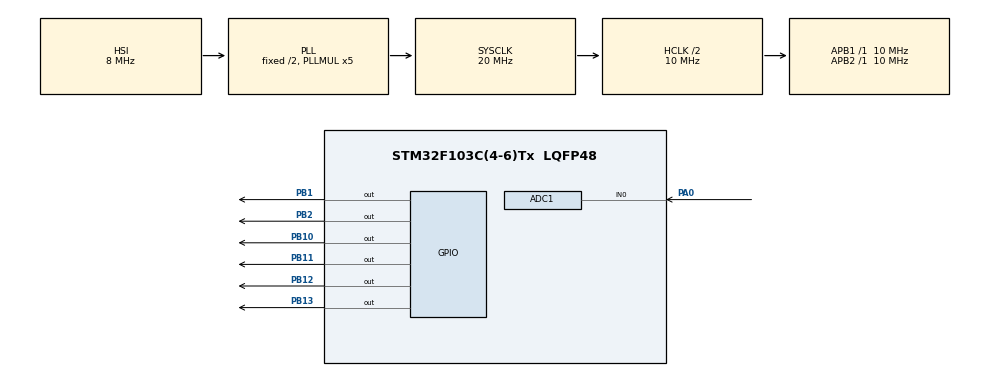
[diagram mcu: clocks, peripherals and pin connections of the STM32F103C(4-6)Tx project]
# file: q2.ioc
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ADC1.Channel-0\#ChannelRegularConversion=ADC_CHANNEL_0
ADC1.NbrOfConversionFlag=1
ADC1.Rank-0\#ChannelRegularConversion=1
ADC1.SamplingTime-0\#ChannelRegularConversion=ADC_SAMPLETIME_1CYCLE_5
ADC1.master=1
Mcu.Family=STM32F1
Mcu.Name=STM32F103C(4-6)Tx
Mcu.Package=LQFP48
NVIC.PriorityGroup=NVIC_PRIORITYGROUP_4
PA0-WKUP.Signal=ADCx_IN0
PB1.Signal=GPIO_Output
PB10.Signal=GPIO_Output
PB11.Signal=GPIO_Output
PB12.Signal=GPIO_Output
PB13.Signal=GPIO_Output
PB2.Signal=GPIO_Output
ProjectManager.HeapSize=0x200
ProjectManager.StackSize=0x400
ProjectManager.TargetToolchain=STM32CubeIDE
RCC.AHBCLKDivider=RCC_SYSCLK_DIV2
RCC.AHBFreq_Value=10000000
RCC.APB1Freq_Value=10000000
RCC.APB1TimFreq_Value=10000000
RCC.APB2Freq_Value=10000000
RCC.APB2TimFreq_Value=10000000
RCC.HCLKFreq_Value=10000000
RCC.PLLMUL=RCC_PLL_MUL5
RCC.SYSCLKFreq_VALUE=20000000
RCC.SYSCLKSource=RCC_SYSCLKSOURCE_PLLCLK
RCC.USBFreq_Value=20000000
SH.ADCx_IN0.0=ADC1_IN0,IN0
VP_SYS_VS_ND.Mode=No_Debug
board=custom

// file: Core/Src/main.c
/* USER CODE BEGIN Header */
/* USER CODE END Header */
#include "main.h"
#include "codenic_lcd.h"
#include <stdio.h>
extern ADC_HandleTypeDef hadc1;

/* USER CODE BEGIN Includes */
extern ADC_HandleTypeDef hadc1;

/* USER CODE END Includes */

/* USER CODE BEGIN PD */
char buffer[20];
uint32_t adc_value;

/* USER CODE END PD */

ADC_HandleTypeDef hadc1;

void SystemClock_Config(void);
static void MX_GPIO_Init(void);
static void MX_ADC1_Init(void);

int main(void)
{

  /* MCU Configuration--------------------------------------------------------*/

  /* Reset of all peripherals, Initializes the Flash interface and the Systick. */
  HAL_Init();

  /* Configure the system clock */
  SystemClock_Config();

  /* Initialize all configured peripherals */
  MX_GPIO_Init();
  MX_ADC1_Init();
  /* USER CODE BEGIN 2 */
  LCD_Init();
  LCD_SetCursor(0, 0);
  /* USER CODE END 2 */

  /* Infinite loop */
  /* USER CODE BEGIN WHILE */

  while (1)
      {

	          HAL_ADC_Start(&hadc1);
	          HAL_ADC_PollForConversion(&hadc1, 1000);
	          adc_value = HAL_ADC_GetValue(&hadc1);
	          HAL_ADC_Stop(&hadc1);
	          LCD_SetCursor(0, 0);
	          LCD_PrintFloat(adc_value, 2);
	          LCD_SetCursor(0, 1);
	          float voltage = adc_value / 819.0f ;
	          LCD_PrintFloat((100.2 * voltage +0.5887), 2);

	          //LCD_SetCursor(0, 0);

	          //sprintf(buffer, "%lu", adc_value);

      }
    /* USER CODE END WHILE */

}

void SystemClock_Config(void)
{
  RCC_OscInitTypeDef RCC_OscInitStruct = {0};
  RCC_ClkInitTypeDef RCC_ClkInitStruct = {0};
  RCC_PeriphCLKInitTypeDef PeriphClkInit = {0};

  /** Initializes the RCC Oscillators according to the specified parameters
  * in the RCC_OscInitTypeDef structure.
  */
  RCC_OscInitStruct.OscillatorType = RCC_OSCILLATORTYPE_HSI;
  RCC_OscInitStruct.HSIState = RCC_HSI_ON;
  RCC_OscInitStruct.HSICalibrationValue = RCC_HSICALIBRATION_DEFAULT;
  RCC_OscInitStruct.PLL.PLLState = RCC_PLL_ON;
  RCC_OscInitStruct.PLL.PLLSource = RCC_PLLSOURCE_HSI_DIV2;
  RCC_OscInitStruct.PLL.PLLMUL = RCC_PLL_MUL5;
  if (HAL_RCC_OscConfig(&RCC_OscInitStruct) != HAL_OK)
  {
    Error_Handler();
  }

  /** Initializes the CPU, AHB and APB buses clocks
  */
  RCC_ClkInitStruct.ClockType = RCC_CLOCKTYPE_HCLK|RCC_CLOCKTYPE_SYSCLK
                              |RCC_CLOCKTYPE_PCLK1|RCC_CLOCKTYPE_PCLK2;
  RCC_ClkInitStruct.SYSCLKSource = RCC_SYSCLKSOURCE_PLLCLK;
  RCC_ClkInitStruct.AHBCLKDivider = RCC_SYSCLK_DIV2;
  RCC_ClkInitStruct.APB1CLKDivider = RCC_HCLK_DIV1;
  RCC_ClkInitStruct.APB2CLKDivider = RCC_HCLK_DIV1;

  if (HAL_RCC_ClockConfig(&RCC_ClkInitStruct, FLASH_LATENCY_0) != HAL_OK)
  {
    Error_Handler();
  }
  PeriphClkInit.PeriphClockSelection = RCC_PERIPHCLK_ADC;
  PeriphClkInit.AdcClockSelection = RCC_ADCPCLK2_DIV2;
  if (HAL_RCCEx_PeriphCLKConfig(&PeriphClkInit) != HAL_OK)
  {
    Error_Handler();
  }
}

static void MX_ADC1_Init(void)
{

  ADC_ChannelConfTypeDef sConfig = {0};

  /** Common config
  */
  hadc1.Instance = ADC1;
  hadc1.Init.ScanConvMode = ADC_SCAN_DISABLE;
  hadc1.Init.ContinuousConvMode = ENABLE;
  hadc1.Init.DiscontinuousConvMode = DISABLE;
  hadc1.Init.ExternalTrigConv = ADC_SOFTWARE_START;
  hadc1.Init.DataAlign = ADC_DATAALIGN_RIGHT;
  hadc1.Init.NbrOfConversion = 1;
  if (HAL_ADC_Init(&hadc1) != HAL_OK)
  {
    Error_Handler();
  }

  /** Configure Regular Channel
  */
  sConfig.Channel = ADC_CHANNEL_0;
  sConfig.Rank = ADC_REGULAR_RANK_1;
  sConfig.SamplingTime = ADC_SAMPLETIME_1CYCLE_5;
  if (HAL_ADC_ConfigChannel(&hadc1, &sConfig) != HAL_OK)
  {
    Error_Handler();
  }

}

static void MX_GPIO_Init(void)
{
  GPIO_InitTypeDef GPIO_InitStruct = {0};

  /* GPIO Ports Clock Enable */
  __HAL_RCC_GPIOA_CLK_ENABLE();
  __HAL_RCC_GPIOB_CLK_ENABLE();

  /*Configure GPIO pin Output Level */
  HAL_GPIO_WritePin(GPIOB, GPIO_PIN_1|GPIO_PIN_2|GPIO_PIN_10|GPIO_PIN_11
                          |GPIO_PIN_12|GPIO_PIN_13, GPIO_PIN_RESET);

  /*Configure GPIO pins : PB1 PB2 PB10 PB11
                           PB12 PB13 */

  GPIO_InitStruct.Pin = GPIO_PIN_1|GPIO_PIN_2|GPIO_PIN_10|GPIO_PIN_11|GPIO_PIN_12|GPIO_PIN_13;
  GPIO_InitStruct.Mode = GPIO_MODE_OUTPUT_PP;
  GPIO_InitStruct.Pull = GPIO_NOPULL;
  GPIO_InitStruct.Speed = GPIO_SPEED_FREQ_LOW;
  HAL_GPIO_Init(GPIOB, &GPIO_InitStruct);

}

void Error_Handler(void)
{
}
